# platform_designer_hps_system_hps_0_hps register map
Vendor: default_vendor.com; File version: 0.0
Registers are 32-bit, read-write, reset 0x0 unless marked. A register's access mark holds for its fields unless they carry their own. Offsets are from the block's base; [hi:lo] are bit positions; lines under a group give offsets from that group; {n}, {i} and the like mark numbered series.

## emac0 (part 5 of 5) — Registers in the EMAC module.
Base 0xFF700000
Same registers: emac1 0xFF702000
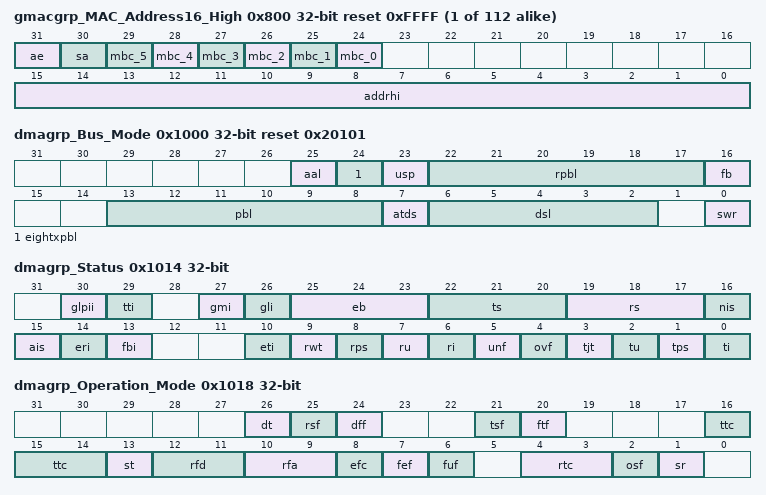
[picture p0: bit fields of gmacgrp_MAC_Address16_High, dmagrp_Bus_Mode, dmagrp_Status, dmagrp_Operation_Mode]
{0x780+8i} gmacgrp_MAC_Address{i}_High reset 0xFFFF (i=16..127) — The MAC Address{i} High register holds the upper 16 bits of the {i+1}th 6-byte MAC address of the station. Because the MAC address registers are configured to be double-synchronized to the (G)MII clock domains, the synchronization is triggered only when bits[31:24] (in little-endian mode) or Bits[7:0] (in big-endian mode) of the MAC Address{i} Low Register are written. For proper synchronization updates, the consecutive writes to this Address Low Register should be performed after at least four clock cycles in the destination clock domain. Note that all MAC Address High registers (except MAC Address0 High) have the same format.
  [31] ae — When this bit is enabled, the address filter block uses the {i+1}th MAC address for perfect filtering. When this bit is disabled, the address filter block ignores the address for filtering.
    0=disabled; 1=enabled
  [30] sa — When this bit is enabled, the MAC Address{i}[47:0] is used to compare with the SA fields of the received frame. When this bit is disabled, the MAC Address{i}[47:0] is used to compare with the DA fields of the received frame.
    0=disabled; 1=enabled
  [n+24] mbc_{n} (n=0..5) — This array of bits are mask control bits for comparison of each of the MAC Address bytes. When masked, the MAC does not compare the corresponding byte of received DA or SA with the contents of MAC Address{i} high and low registers. Each bit controls the masking of the bytes. You can filter a group of addresses (known as group address filtering) by masking one or more bytes of the address. The array index corresponds to the byte (e.g. index 0 is for bits 7:0).
    0=unmasked; 1=masked
  [15:0] addrhi — This field contains the upper 16 bits (47:32) of the {i+1}th 6-byte MAC address.
{0x784+8i} gmacgrp_MAC_Address{i}_Low reset 0xFFFFFFFF (i=16..127) — The MAC Address{i} Low register holds the lower 32 bits of the {i+1}th 6-byte MAC address of the station. Note that all MAC Address Low registers (except MAC Address0 Low) have the same format.
  [31:0] addrlo — This field contains the lower 32 bits of the {i+1}th 6-byte MAC address. The content of this field is undefined until loaded by software after the initialization process.
0x1000 dmagrp_Bus_Mode reset 0x20101 — The Bus Mode register establishes the bus operating modes for the DMA.
  [25] aal — When this bit is set high and the FB bit is equal to 1, the AHB or AXI interface generates all bursts aligned to the start address LS bits. If the FB bit is equal to 0, the first burst (accessing the data buffer's start address) is not aligned, but subsequent bursts are aligned to the address.
    0=disabled; 1=enabled
  [24] eightxpbl — When set high, this bit multiplies the programmed PBL value (Bits[22:17] and Bits[13:8]) eight times. Therefore, the DMA transfers the data in 8, 16, 32, 64, 128, and 256 beats depending on the PBL value.
    0=disabled; 1=enabled
  [23] usp — When set high, this bit configures the Rx DMA to use the value configured in Bits[22:17] as PBL. The PBL value in Bits[13:8] is applicable only to the Tx DMA operations. When reset to low, the PBL value in Bits[13:8] is applicable for both DMA engines.
    0=disabled; 1=enabled
  [22:17] rpbl — This field indicates the maximum number of beats to be transferred in one Rx DMA transaction. This is the maximum value that is used in a single block Read or Write. The Rx DMA always attempts to burst as specified in the RPBL bit each time it starts a Burst transfer on the host bus. You can program RPBL with values of 1, 2, 4, 8, 16, and 32. Any other value results in undefined behavior. This field is valid and applicable only when USP is set high.
    1=rxdmapbl1; 2=rxdmapbl2; 4=rxdmapbl4; 8=rxdmapbl8; 16=rxdmapbl6; 32=rxdmapbl32
  [16] fb — This bit controls whether the AXI Master interface performs fixed burst transfers or not. When set, the AXI interface uses FIXED bursts during the start of the normal burst transfers. When reset, the AXI interface uses SINGLE and INCR burst transfer operations. For more information, see Bit 0 (UNDEFINED) of the AXI Bus Mode register.
    0=nonfb; 1=fb1_4_8_16
  [13:8] pbl — These bits indicate the maximum number of beats to be transferred in one DMA transaction. This is the maximum value that is used in a single block Read or Write. The DMA always attempts to burst as specified in PBL each time it starts a Burst transfer on the host bus. PBL can be programmed with permissible values of 1, 2, 4, 8, 16, and 32. Any other value results in undefined behavior. When USP is set high, this PBL value is applicable only for Tx DMA transactions. If the number of beats to be transferred is more than 32, then perform the following steps: 1. Set the 8xPBL mode. 2. Set the PBL. For example, if the maximum number of beats to be transferred is 64, then first set 8xPBL to 1 and then set PBL to 8. The PBL values have the following limitation: The maximum number of possible beats (PBL) is limited by the size of the Tx FIFO and Rx FIFO in the MTL layer and the data bus width on the DMA. The FIFO has a constraint that the maximum beat supported is half the depth of the FIFO, except when specified.
  [7] atds — When set, the size of the alternate descriptor increases to 32 bytes (8 DWORDS). This is required when the Advanced Timestamp feature or the IPC Full Offload Engine (Type 2) is enabled in the receiver. The enhanced descriptor is not required if the Advanced Timestamp and IPC Full Checksum Offload (Type 2) features are not enabled. In such cases, you can use the 16 bytes descriptor to save 4 bytes of memory. When reset, the descriptor size reverts back to 4 DWORDs (16 bytes). This bit preserves the backward compatibility for the descriptor size. In versions prior to 3.50a, the descriptor size is 16 bytes for both normal and enhanced descriptor. In version 3.50a, descriptor size is increased to 32 bytes because of the Advanced Timestamp and IPC Full Checksum Offload Engine (Type 2) features.
    0=clearrst; 1=reset
  [6:2] dsl — This bit specifies the number of Word, Dword, or Lword (depending on the 32-bit, 64-bit, or 128-bit bus) to skip between two unchained descriptors. The address skipping starts from the end of current descriptor to the start of next descriptor. When the DSL value is equal to zero, then the descriptor table is taken as contiguous by the DMA in Ring mode.
  [0] swr — When this bit is set, the MAC DMA Controller resets the logic and all internal registers of the MAC. It is cleared automatically after the reset operation has completed in all of the EMAC clock domains. Before reprogramming any register of the EMAC, you should read a zero (0) value in this bit . Note: * The Software reset function is driven only by this bit. Bit 0 of Register 64 (Channel 1 Bus Mode Register) or Register 128 (Channel 2 Bus Mode Register) has no impact on the Software reset function. * The reset operation is completed only when all resets in all active clock domains are de-asserted. Therefore, it is essential that all the PHY inputs clocks (applicable for the selected PHY interface) are present for the software reset completion.
    0=clearrst; 1=reset
0x1004 dmagrp_Transmit_Poll_Demand — The Transmit Poll Demand register enables the Tx DMA to check whether or not the DMA owns the current descriptor. The Transmit Poll Demand command is given to wake up the Tx DMA if it is in the Suspend mode. The Tx DMA can go into the Suspend mode because of an Underflow error in a transmitted frame or the unavailability of descriptors owned by it. You can give this command anytime and the Tx DMA resets this command when it again starts fetching the current descriptor from host memory.
  [31:0] tpd — When these bits are written with any value, the DMA reads the current descriptor pointed to by Register 18 (Current Host Transmit Descriptor Register). If that descriptor is not available (owned by the Host), the transmission returns to the Suspend state and the Bit 2 (TU) of Register 5 (Status Register) is asserted. If the descriptor is available, the transmission resumes.
0x1008 dmagrp_Receive_Poll_Demand — The Receive Poll Demand register enables the receive DMA to check for new descriptors. This command is used to wake up the Rx DMA from the SUSPEND state. The RxDMA can go into the SUSPEND state only because of the unavailability of descriptors it owns.
  [31:0] rpd — When these bits are written with any value, the DMA reads the current descriptor pointed to by Register 19 (Current Host Receive Descriptor Register). If that descriptor is not available (owned by the Host), the reception returns to the Suspended state and the Bit 7 (RU) of Register 5 (Status Register) is not asserted. If the descriptor is available, the Rx DMA returns to the active state.
0x100C dmagrp_Receive_Descriptor_List_Address — The Receive Descriptor List Address register points to the start of the Receive Descriptor List. The descriptor lists reside in the host's physical memory space and must be Word, Dword, or Lword-aligned (for 32-bit, 64-bit, or 128-bit data bus). The DMA internally converts it to bus width aligned address by making the corresponding LS bits low. Writing to this register is permitted only when reception is stopped. When stopped, this register must be written to before the receive Start command is given. You can write to this register only when Rx DMA has stopped, that is, Bit 1 (SR) is set to zero in Register 6 (Operation Mode Register). When stopped, this register can be written with a new descriptor list address. When you set the SR bit to 1, the DMA takes the newly programmed descriptor base address. If this register is not changed when the SR bit is set to 0, then the DMA takes the descriptor address where it was stopped earlier.
  [31:2] rdesla_32bit — This field contains the base address of the first descriptor in the Receive Descriptor list. The LSB bits (1:0) are ignored (32-bit wide bus) and internally taken as all-zero by the DMA. Therefore, these LSB bits are read-only (RO).
0x1010 dmagrp_Transmit_Descriptor_List_Address — The Transmit Descriptor List Address register points to the start of the Transmit Descriptor List. The descriptor lists reside in the host's physical memory space and must be Word, Dword, or Lword-aligned (for 32-bit, 64-bit, or 128-bit data bus). The DMA internally converts it to bus width aligned address by making the corresponding LSB to low. You can write to this register only when the Tx DMA has stopped, that is, Bit 13 (ST) is set to zero in Register 6 (Operation Mode Register). When stopped, this register can be written with a new descriptor list address. When you set the ST bit to 1, the DMA takes the newly programmed descriptor base address. If this register is not changed when the ST bit is set to 0, then the DMA takes the descriptor address where it was stopped earlier.
  [31:2] tdesla_32bit — This field contains the base address of the first descriptor in the Transmit Descriptor list. The LSB bits (1:0) are ignored (32-bit wide bus) and are internally taken as all-zero by the DMA. Therefore, these LSB bits are read-only (RO).
0x1014 dmagrp_Status — The Status register contains all status bits that the DMA reports to the host. The software driver reads this register during an interrupt service routine or polling. Most of the fields in this register cause the host to be interrupted. The bits of this register are not cleared when read. Writing 1'b1 to (unreserved) Bits[16:0] of this register clears these bits and writing 1'b0 has no effect. Each field (Bits[16:0]) can be masked by masking the appropriate bit in Register 7 (Interrupt Enable Register).
  [30] glpii ro — This bit indicates an interrupt event in the LPI logic of the EMAC. To reset this bit to 1'b0, the software must read the corresponding registers in the EMAC to get the exact cause of the interrupt and clear its source. When this bit is high, the interrupt signal from the MAC (sbd_intr_o) is high.
    0=nointerrup; 1=interrup
  [29] tti ro — This bit indicates an interrupt event in the Timestamp Generator block of EMAC. The software must read the corresponding registers in the EMAC to get the exact cause of interrupt and clear its source to reset this bit to 1'b0. When this bit is high, the interrupt signal from the EMAC subsystem (sbd_intr_o) is high.
    0=nointerrup; 1=interrup
  [27] gmi ro — This bit reflects an interrupt event in the MMC block of the EMAC. The software must read the corresponding registers in the EMAC to get the exact cause of interrupt and clear the source of interrupt to make this bit as 1'b0. The interrupt signal from the EMAC subsystem (sbd_intr_o) is high when this bit is high.
    0=nointerrup; 1=interrup
  [26] gli ro — This bit reflects an interrupt event in the PCS (link change and AN complete), SMII (link change), or RGMII (link change) interface block of the EMAC. The software must read the corresponding registers (Register 49 for PCS or Register 54 for SMII or RGMII) in the EMAC to get the exact cause of the interrupt and clear the source of interrupt to make this bit as 1'b0. The interrupt signal from the EMAC subsystem (sbd_intr_o) is high when this bit is high.
    0=nointerrup; 1=interrup
  [25:23] eb ro — This field indicates the type of error that caused a Bus Error, for example, error response on the AHB or AXI interface. This field is valid only when Bit 13 (FBI) is set. This field does not generate an interrupt. * Bit 23 - 1'b1: Error during data transfer by the Tx DMA - 1'b0: Error during data transfer by the Rx DMA * Bit 24 - 1'b1: Error during read transfer - 1'b0: Error during write transfer * Bit 25 - 1'b1: Error during descriptor access - 1'b0: Error during data buffer access
  [22:20] ts ro — This field indicates the Transmit DMA FSM state. This field does not generate an interrupt.
    0=stopped; 1=runfetch; 2=runwait; 3=runread; 4=timestmp; 5=reserve; 6=susptx; 7=runclose
  [19:17] rs ro — This field indicates the Receive DMA FSM state. This field does not generate an interrupt.
    0=stopped; 1=runfetch; 2=reserve; 3=runwait; 4=suspend; 5=runclose; 6=timestmp; 7=runtrans
  [16] nis — Normal Interrupt Summary bit value is the logical OR of the following when the corresponding interrupt bits are enabled in Register 7 (Interrupt Enable Register): * Register 5[0]: Transmit Interrupt * Register 5[2]: Transmit Buffer Unavailable * Register 5[6]: Receive Interrupt * Register 5[14]: Early Receive Interrupt Only unmasked bits (interrupts for which interrupt enable is set in Register 7) affect the Normal Interrupt Summary bit. This is a sticky bit and must be cleared (by writing 1 to this bit) each time a corresponding bit, which causes NIS to be set, is cleared.
  [15] ais — Abnormal Interrupt Summary bit value is the logical OR of the following when the corresponding interrupt bits are enabled in Register 7 (Interrupt Enable Register): * Register 5[1]: Transmit Process Stopped * Register 5[3]: Transmit Jabber Timeout * Register 5[4]: Receive FIFO Overflow * Register 5[5]: Transmit Underflow * Register 5[7]: Receive Buffer Unavailable * Register 5[8]: Receive Process Stopped * Register 5[9]: Receive Watchdog Timeout * Register 5[10]: Early Transmit Interrupt * Register 5[13]: Fatal Bus Error Only unmasked bits affect the Abnormal Interrupt Summary bit. This is a sticky bit and must be cleared each time a corresponding bit, which causes AIS to be set, is cleared.
  [14] eri — This bit indicates that the DMA had filled the first data buffer of the packet. Bit 6 (RI) of this register automatically clears this bit.
  [13] fbi — This bit indicates that a bus error occurred, as described in Bits[25:23]. When this bit is set, the corresponding DMA engine disables all of its bus accesses.
  [10] eti — This bit indicates that the frame to be transmitted is fully transferred to the MTL Transmit FIFO.
  [9] rwt — This bit is asserted when a frame with length greater than 2,048 bytes is received (10, 240 when Jumbo Frame mode is enabled).
  [8] rps — This bit is asserted when the Receive Process enters the Stopped state.
  [7] ru — This bit indicates that the host owns the Next Descriptor in the Receive List and the DMA cannot acquire it. The Receive Process is suspended. To resume processing Receive descriptors, the host should change the ownership of the descriptor and issue a Receive Poll Demand command. If no Receive Poll Demand is issued, the Receive Process resumes when the next recognized incoming frame is received. This bit is set only when the previous Receive Descriptor is owned by the DMA.
  [6] ri — This bit indicates that the frame reception is complete. When reception is complete, the Bit 31 of RDES1 (Disable Interrupt on Completion) is reset in the last Descriptor, and the specific frame status information is updated in the descriptor. The reception remains in the Running state.
  [5] unf — This bit indicates that the Transmit Buffer had an Underflow during frame transmission. Transmission is suspended and an Underflow Error TDES0[1] is set.
  [4] ovf — This bit indicates that the Receive Buffer had an Overflow during frame reception. If the partial frame is transferred to the application, the overflow status is set in RDES0[11].
  [3] tjt — This bit indicates that the Transmit Jabber Timer expired, which happens when the frame size exceeds 2,048 (10,240 bytes when the Jumbo frame is enabled). When the Jabber Timeout occurs, the transmission process is aborted and placed in the Stopped state. This causes the Transmit Jabber Timeout TDES0[14] flag to assert.
  [2] tu — This bit indicates that the host owns the Next Descriptor in the Transmit List and the DMA cannot acquire it. Transmission is suspended. Bits[22:20] explain the Transmit Process state transitions. To resume processing Transmit descriptors, the host should change the ownership of the descriptor by setting TDES0[31] and then issue a Transmit Poll Demand command.
  [1] tps — This bit is set when the transmission is stopped.
  [0] ti — This bit indicates that the frame transmission is complete. When transmission is complete, the Bit 31 (Interrupt on Completion) of TDES1 is reset in the first descriptor, and the specific frame status information is updated in the descriptor.
0x1018 dmagrp_Operation_Mode — The Operation Mode register establishes the Transmit and Receive operating modes and commands. This register should be the last CSR to be written as part of the DMA initialization.
  [26] dt — When this bit is set, the MAC does not drop the frames which only have errors detected by the Receive Checksum Offload engine. Such frames do not have any errors (including FCS error) in the Ethernet frame received by the MAC but have errors only in the encapsulated payload. When this bit is reset, all error frames are dropped if the FEF bit is reset.
    0=disabled; 1=enabled
  [25] rsf — When this bit is set, the MTL reads a frame from the Rx FIFO only after the complete frame has been written to it, ignoring the RTC bits. When this bit is reset, the Rx FIFO operates in the cut-through mode, subject to the threshold specified by the RTC bits.
    0=disabled; 1=enabled
  [24] dff — When this bit is set, the Rx DMA does not flush any frames because of the unavailability of receive descriptors or buffers as it does normally when this bit is reset.
    0=disabled; 1=enabled
  [21] tsf — When this bit is set, transmission starts when a full frame resides in the MTL Transmit FIFO. When this bit is set, the TTC values specified in Bits[16:14] are ignored. This bit should be changed only when the transmission is stopped.
    0=disabled; 1=enabled
  [20] ftf — When this bit is set, the transmit FIFO controller logic is reset to its default values and thus all data in the Tx FIFO is lost or flushed. This bit is cleared internally when the flushing operation is completed. The Operation Mode register should not be written to until this bit is cleared. The data which is already accepted by the MAC transmitter is not flushed. It is scheduled for transmission and results in underflow and runt frame transmission. Note: The flush operation is complete only when the Tx FIFO is emptied of its contents and all the pending Transmit Status of the transmitted frames are accepted by the host. To complete this flush operation, the PHY transmit clock is required to be active.
    0=disabled; 1=enabled
  [16:14] ttc — These bits control the threshold level of the MTL Transmit FIFO. Transmission starts when the frame size within the MTL Transmit FIFO is larger than the threshold. In addition, full frames with a length less than the threshold are also transmitted. These bits are used only when Bit 21 (TSF) is reset.
    0=ttcthesh64; 1=ttcthres128; 2=ttcthres192; 3=ttcthres256; 4=ttcthres40; 5=ttcthres32; 6=ttcthres24; 7=ttcthres16
  [13] st — When this bit is set, transmission is placed in the Running state, and the DMA checks the Transmit List at the current position for a frame to be transmitted. Descriptor acquisition is attempted either from the current position in the list, which is the Transmit List Base Address set by Register 4 (Transmit Descriptor List Address Register), or from the position retained when transmission was stopped previously. If the DMA does not own the current descriptor, transmission enters the Suspended state and Bit 2 (Transmit Buffer Unavailable) of Register 5 (Status Register) is set. The Start Transmission command is effective only when transmission is stopped. If the command is issued before setting Register 4 (Transmit Descriptor List Address Register), then the DMA behavior is unpredictable. When this bit is reset, the transmission process is placed in the Stopped state after completing the transmission of the current frame. The Next Descriptor position in the Transmit List is saved, and it becomes the current position when transmission is restarted. To change the list address, you need to program Register 4 (Transmit Descriptor List Address Register) with a new value when this bit is reset. The new value is considered when this bit is set again. The stop transmission command is effective only when the transmission of the current frame is complete or the transmission is in the Suspended state.
    0=disabled; 1=enabled
  [12:11] rfd — These bits control the threshold (Fill-level of Rx FIFO) at which the flow control is de-asserted after activation. The de-assertion is effective only after flow control is asserted.
    {v}=fifofull_{v+1}k (v=0..3)
  [10:9] rfa — These bits control the threshold (Fill level of Rx FIFO) at which the flow control is activated. These values only apply to the Rx FIFO when the EFC bit is set high.
    {v}=fifofull_{v+1}k (v=0..3)
  [8] efc — When this bit is set, the flow control signal operation based on the fill-level of Rx FIFO is enabled. When reset, the flow control operation is disabled.
    0=disabled; 1=enabled
  [7] fef — When this bit is reset, the Rx FIFO drops frames with error status (CRC error, collision error, GMII_ER, giant frame, watchdog timeout, or overflow). However, if the start byte (write) pointer of a frame is already transferred to the read controller side (in Threshold mode), then the frame is not dropped. When the FEF bit is set, all frames except runt error frames are forwarded to the DMA. If the Bit 25 (RSF) is set and the Rx FIFO overflows when a partial frame is written, then the frame is dropped irrespective of the FEF bit setting. However, if the Bit 25 (RSF) is reset and the Rx FIFO overflows when a partial frame is written, then a partial frame may be forwarded to the DMA.
    0=disabled; 1=enabled
  [6] fuf — When set, the Rx FIFO forwards Undersized frames (frames with no Error and length less than 64 bytes) including pad-bytes and CRC. When reset, the Rx FIFO drops all frames of less than 64 bytes, unless a frame is already transferred because of the lower value of Receive Threshold, for example, RTC = 01.
    0=disabled; 1=enabled
  [4:3] rtc — These two bits control the threshold level of the MTL Receive FIFO. Transfer (request) to DMA starts when the frame size within the MTL Receive FIFO is larger than the threshold. In addition, full frames with length less than the threshold are transferred automatically. These bits are valid only when the RSF bit is zero, and are ignored when the RSF bit is set to 1.
    0=thrfifo64; 1=thrfifo32; 2=thrfifo96; 3=thrfifo128
  [2] osf — When this bit is set, it instructs the DMA to process the second frame of the Transmit data even before the status for the first frame is obtained.
    0=disabled; 1=enabled
  [1] sr — When this bit is set, the Receive process is placed in the Running state. The DMA attempts to acquire the descriptor from the Receive list and processes the incoming frames. The descriptor acquisition is attempted from the current position in the list, which is the address set by Register 3 (Receive Descriptor List Address Register) or the position retained when the Receive process was previously stopped. If the DMA does not own the descriptor, reception is suspended and Bit 7 (Receive Buffer Unavailable) of Register 5 (Status Register) is set. The Start Receive command is effective only when the reception has stopped. If the command is issued before setting Register 3 (Receive Descriptor List Address Register), the DMA behavior is unpredictable. When this bit is cleared, the Rx DMA operation is stopped after the transfer of the current frame. The next descriptor position in the Receive list is saved and becomes the current position after the Receive process is restarted. The Stop Receive command is effective only when the Receive process is in either the Running (waiting for receive packet) or in the Suspended state.
    0=disabled; 1=enabled
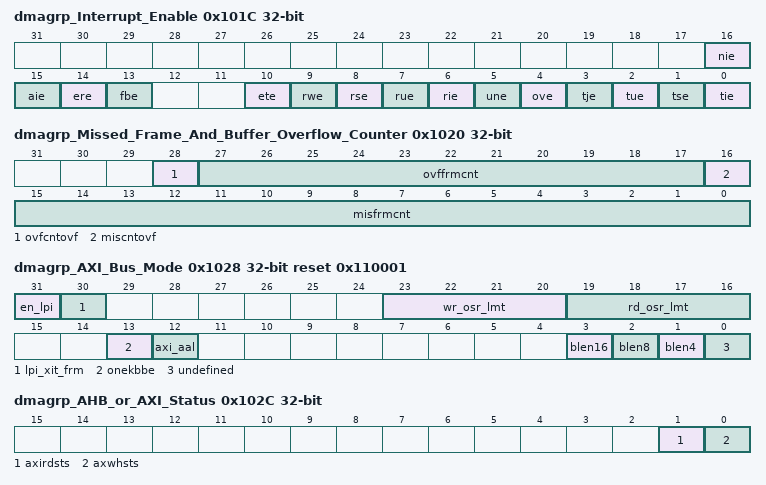
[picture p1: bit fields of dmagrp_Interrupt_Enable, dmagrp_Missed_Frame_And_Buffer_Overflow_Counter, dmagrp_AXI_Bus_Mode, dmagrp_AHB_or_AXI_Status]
0x101C dmagrp_Interrupt_Enable — The Interrupt Enable register enables the interrupts reported by Register 5 (Status Register). Setting a bit to 1'b1 enables a corresponding interrupt. After a hardware or software reset, all interrupts are disabled.
  [16] nie — When this bit is set, normal interrupt summary is enabled. When this bit is reset, normal interrupt summary is disabled. This bit enables the following interrupts in Register 5 (Status Register): * Register 5[0]: Transmit Interrupt * Register 5[2]: Transmit Buffer Unavailable * Register 5[6]: Receive Interrupt * Register 5[14]: Early Receive Interrupt
    0=disabled; 1=enabled
  [15] aie — When this bit is set, abnormal interrupt summary is enabled. When this bit is reset, the abnormal interrupt summary is disabled. This bit enables the following interrupts in Register 5 (Status Register): * Register 5[1]: Transmit Process Stopped * Register 5[3]: Transmit Jabber Timeout * Register 5[4]: Receive Overflow * Register 5[5]: Transmit Underflow * Register 5[7]: Receive Buffer Unavailable * Register 5[8]: Receive Process Stopped * Register 5[9]: Receive Watchdog Timeout * Register 5[10]: Early Transmit Interrupt * Register 5[13]: Fatal Bus Error
    0=disabled; 1=enabled
  [14] ere — When this bit is set with Normal Interrupt Summary Enable (Bit 16), the Early Receive Interrupt is enabled. When this bit is reset, the Early Receive Interrupt is disabled.
    0=disabled; 1=enabled
  [13] fbe — When this bit is set with Abnormal Interrupt Summary Enable (Bit 15), the Fatal Bus Error Interrupt is enabled. When this bit is reset, the Fatal Bus Error Enable Interrupt is disabled.
    0=disabled; 1=enabled
  [10] ete — When this bit is set with an Abnormal Interrupt Summary Enable (Bit 15), the Early Transmit Interrupt is enabled. When this bit is reset, the Early Transmit Interrupt is disabled.
    0=disabled; 1=enabled
  [9] rwe — When this bit is set with Abnormal Interrupt Summary Enable (Bit 15), the Receive Watchdog Timeout Interrupt is enabled. When this bit is reset, the Receive Watchdog Timeout Interrupt is disabled.
    0=disabled; 1=enabled
  [8] rse — When this bit is set with Abnormal Interrupt Summary Enable (Bit 15), the Receive Stopped Interrupt is enabled. When this bit is reset, the Receive Stopped Interrupt is disabled.
    0=disabled; 1=enabled
  [7] rue — When this bit is set with Abnormal Interrupt Summary Enable (Bit 15), the Receive Buffer Unavailable Interrupt is enabled. When this bit is reset, the Receive Buffer Unavailable Interrupt is disabled.
  [6] rie — When this bit is set with Normal Interrupt Summary Enable (Bit 16), the Receive Interrupt is enabled. When this bit is reset, the Receive Interrupt is disabled.
    0=disabled; 1=enabled
  [5] une — When this bit is set with Abnormal Interrupt Summary Enable (Bit 15), the Transmit Underflow Interrupt is enabled. When this bit is reset, the Underflow Interrupt is disabled.
    0=disabled; 1=enabled
  [4] ove — When this bit is set with Abnormal Interrupt Summary Enable (Bit 15), the Receive Overflow Interrupt is enabled. When this bit is reset, the Overflow Interrupt is disabled.
    0=disabled; 1=enabled
  [3] tje — When this bit is set with Abnormal Interrupt Summary Enable (Bit 15), the Transmit Jabber Timeout Interrupt is enabled. When this bit is reset, the Transmit Jabber Timeout Interrupt is disabled.
    0=disabled; 1=enabled
  [2] tue — When this bit is set with Normal Interrupt Summary Enable (Bit 16), the Transmit Buffer Unavailable Interrupt is enabled. When this bit is reset, the Transmit Buffer Unavailable Interrupt is disabled.
    0=disabled; 1=enabled
  [1] tse — When this bit is set with Abnormal Interrupt Summary Enable (Bit 15), the Transmission Stopped Interrupt is enabled. When this bit is reset, the Transmission Stopped Interrupt is disabled.
    0=disabled; 1=enabled
  [0] tie — When this bit is set with Normal Interrupt Summary Enable (Bit 16), the Transmit Interrupt is enabled. When this bit is reset, the Transmit Interrupt is disabled.
    0=disabled; 1=enabled
0x1020 dmagrp_Missed_Frame_And_Buffer_Overflow_Counter ro — The DMA maintains two counters to track the number of frames missed during reception. This register reports the current value of the counter. The counter is used for diagnostic purposes. Bits[15:0] indicate missed frames because of the host buffer being unavailable. Bits[27:17] indicate missed frames because of buffer overflow conditions (MTL and MAC) and runt frames (good frames of less than 64 bytes) dropped by the MTL.
  [28] ovfcntovf — Overflow bit for FIFO Overflow Counter
  [27:17] ovffrmcnt — This field indicates the number of frames missed by the application. This counter is incremented each time the MTL asserts the sideband signal mtl_rxoverflow_o. The counter is cleared when this register is read with mci_be_i[2] at 1'b1.
  [16] miscntovf — Overflow bit for Missed Frame Counter
  [15:0] misfrmcnt — This field indicates the number of frames missed by the controller because of the Host Receive Buffer being unavailable. This counter is incremented each time the DMA discards an incoming frame. The counter is cleared when this register is read with mci_be_i[0] at 1'b1.
0x1024 dmagrp_Receive_Interrupt_Watchdog_Timer — This register, when written with non-zero value, enables the watchdog timer for the Receive Interrupt (Bit 6) of Register 5 (Status Register)
  [7:0] riwt — This bit indicates the number of system clock cycles multiplied by 256 for which the watchdog timer is set. The watchdog timer gets triggered with the programmed value after the Rx DMA completes the transfer of a frame for which the RI status bit is not set because of the setting in the corresponding descriptor RDES1[31]. When the watchdog timer runs out, the RI bit is set and the timer is stopped. The watchdog timer is reset when the RI bit is set high because of automatic setting of RI as per RDES1[31] of any received frame.
0x1028 dmagrp_AXI_Bus_Mode reset 0x110001 — The AXI Bus Mode Register controls the behavior of the AXI master. It is mainly used to control the burst splitting and the number of outstanding requests.
  [31] en_lpi — When set to 1, this bit enables the LPI mode supported by the AXI master and accepts the LPI request from the AXI System Clock controller. When set to 0, this bit disables the LPI mode and always denies the LPI request from the AXI System Clock controller.
    0=disabled; 1=enabled
  [30] lpi_xit_frm — When set to 1, this bit enables the GMAC-AXI to come out of the LPI mode only when the Magic Packet or Remote Wake Up Packet is received. When set to 0, this bit enables the GMAC-AXI to come out of LPI mode when any frame is received.
    0=disabled; 1=enabled
  [23:20] wr_osr_lmt — AXI Maximum Write OutStanding Request Limit
  [19:16] rd_osr_lmt — This value limits the maximum outstanding request on the AXI read interface. Maximum outstanding requests = RD_OSR_LMT+1
  [13] onekbbe — 1 KB Boundary Crossing Enable for the GMAC-AXI Master When set, the GMAC-AXI Master performs burst transfers that do not cross 1 KB boundary. When reset, the GMAC-AXI Master performs burst transfers that do not cross 4 KB boundary.
    0=four_k_boundary; 1=one_k_boundary
  [12] axi_aal ro — This bit is read-only bit and reflects the Bit 25 (AAL) of Register 0 (Bus Mode Register). When this bit is set to 1, the GMAC-AXI performs address-aligned burst transfers on both read and write channels.
    0=disabled; 1=enabled
  [3] blen16 — When this bit is set to 1 or UNDEFINED is set to 1, the GMAC-AXI is allowed to select a burst length of 16 on the AXI Master interface.
    0=disabled; 1=enabled
  [2] blen8 — When this bit is set to 1, the GMAC-AXI is allowed to select a burst length of 8 on the AXI Master interface. Setting this bit has no effect when UNDEFINED is set to 1.
    0=disabled; 1=enabled
  [1] blen4 — When this bit is set to 1, the GMAC-AXI is allowed to select a burst length of 4 on the AXI Master interface. Setting this bit has no effect when UNDEFINED is set to 1.
    0=disabled; 1=enabled
  [0] undefined ro — This bit is read-only bit and indicates the complement (invert) value of Bit 16 (FB) in Register 0 (Bus Mode Register[16]). * When this bit is set to 1, the GMAC-AXI is allowed to perform any burst length equal to or below the maximum allowed burst length programmed in Bits[7:1]. * When this bit is set to 0, the GMAC-AXI is allowed to perform only fixed burst lengths as indicated by BLEN16, BLEN8, or BLEN4, or a burst length of 1.
    0=disabled; 1=enabled
0x102C dmagrp_AHB_or_AXI_Status ro — This register provides the active status of the AXI interface's read and write channels. This register is useful for debugging purposes. In addition, this register is valid only in the Channel 0 DMA when multiple channels are present in the AV mode.
  [1] axirdsts — When high, it indicates that AXI Master's read channel is active and transferring data.
  [0] axwhsts — When high, it indicates that AXI Master's write channel is active and transferring data
0x1048 dmagrp_Current_Host_Transmit_Descriptor ro — The Current Host Transmit Descriptor register points to the start address of the current Transmit Descriptor read by the DMA.
  [31:0] curtdesaptr — Cleared on Reset. Pointer updated by the DMA during operation.
0x104C dmagrp_Current_Host_Receive_Descriptor ro — The Current Host Receive Descriptor register points to the start address of the current Receive Descriptor read by the DMA.
  [31:0] currdesaptr — Cleared on Reset. Pointer updated by the DMA during operation.
0x1050 dmagrp_Current_Host_Transmit_Buffer_Address ro — The Current Host Transmit Buffer Address register points to the current Transmit Buffer Address being read by the DMA.
  [31:0] curtbufaptr — Cleared on Reset. Pointer updated by the DMA during operation.
0x1054 dmagrp_Current_Host_Receive_Buffer_Address ro — The Current Host Receive Buffer Address register points to the current Receive Buffer address being read by the DMA.
  [31:0] currbufaptr — Cleared on Reset. Pointer updated by the DMA during operation.
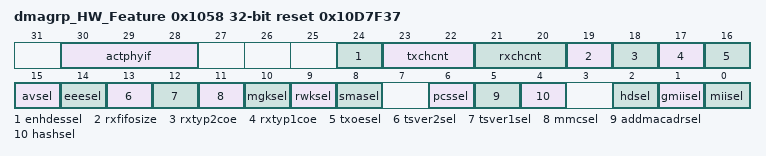
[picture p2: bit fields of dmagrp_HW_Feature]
0x1058 dmagrp_HW_Feature ro reset 0x10D7F37 — This register indicates the presence of the optional features or functions of the gmac. The software driver can use this register to dynamically enable or disable the programs related to the optional blocks.
  [30:28] actphyif — When you have multiple PHY interfaces in your configuration, this field indicates the sampled value of emacx_phy_if_selduring reset de-assertion.
    0=gmiimii0; 1=rgmii1; 2=sgmii2; 3=tbi3; 4=rmii4; 5=rtbi5; 6=smii6; 7=revmii7
  [24] enhdessel — Alternate (Enhanced Descriptor)
    0=disabled; 1=enabled
  [23:22] txchcnt — Number of additional Tx channels
    0=disabled; 1=enabled
  [21:20] rxchcnt — Number of additional Rx channels
    0=disabled; 1=enabled
  [19] rxfifosize — RxFIFO > 2048 Bytes
    0=disabled; 1=enabled
  [18] rxtyp2coe — IP Checksum Offload (Type 2) in Rx
    0=disabled; 1=enabled
  [17] rxtyp1coe — IP Checksum Offload (Type 1) in Rx
    0=disabled; 1=enabled
  [16] txoesel — Checksum Offload in Tx
    0=disabled; 1=enabled
  [15] avsel — AV Feature
    0=disabled; 1=enabled
  [14] eeesel — Energy Efficient Ethernet Feature
    0=disabled; 1=enabled
  [13] tsver2sel — IEEE 1588-2008 Advanced Timestamp
    0=disabled; 1=enabled
  [12] tsver1sel — Only IEEE 1588-2002 Timestamp
    0=disabled; 1=enabled
  [11] mmcsel — RMON block
    0=disabled; 1=enabled
  [10] mgksel — PMT Magic Packet
    0=disabled; 1=enabled
  [9] rwksel — PMT Remote Wakeup support
    0=disabled; 1=enabled
  [8] smasel — SMA (MDIO) Interface support
    0=disabled; 1=enabled
  [6] pcssel — TBI/SGMII/RTBI PHY interface support
    0=disabled; 1=enabled
  [5] addmacadrsel — Multiple MAC Address Registers support
    0=disabled; 1=enabled
  [4] hashsel — HASH Filter support
    0=disabled; 1=enabled
  [2] hdsel — Half-Duplex support
    0=disabled; 1=enabled
  [1] gmiisel — 1000 Mbps support
    0=disabled; 1=enabled
  [0] miisel — 10/100 Mbps support
    0=disabled; 1=enabled
